VERSION ""

NS_ :

BS_:

BU_: XXX

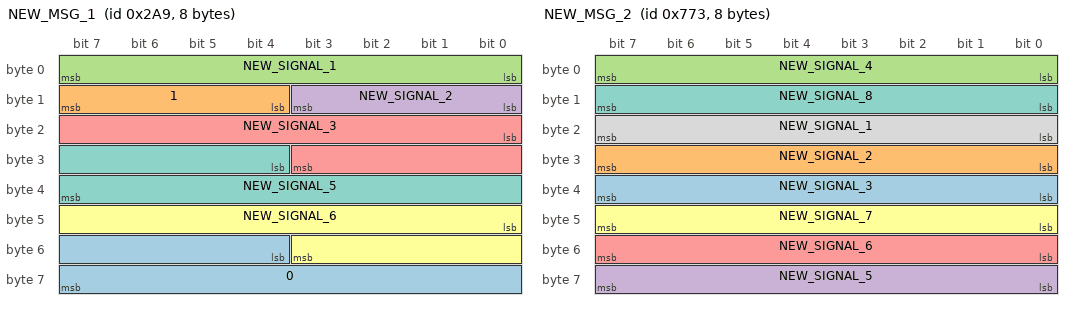
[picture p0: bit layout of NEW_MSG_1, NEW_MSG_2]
BO_ 681 NEW_MSG_1: 8 XXX
 SG_ 0 : 52|12@1+ (1,0) [0|4095] "" XXX
 SG_ 1 : 15|4@0+ (1,0) [0|15] "" XXX
 SG_ NEW_SIGNAL_1 : 0|8@1+ (1,0) [0|255] "" XXX
 SG_ NEW_SIGNAL_2 : 8|4@1+ (1,0) [0|15] "" XXX
 SG_ NEW_SIGNAL_3 : 16|12@1+ (1,0) [0|255] "" XXX
 SG_ NEW_SIGNAL_6 : 40|12@1+ (1,0) [0|255] "" XXX
 SG_ NEW_SIGNAL_5 : 28|12@1+ (1,0) [0|255] "" XXX

BO_ 1907 NEW_MSG_2: 8 XXX
 SG_ NEW_SIGNAL_3 : 32|8@1+ (1,0) [0|255] "" XXX
 SG_ NEW_SIGNAL_2 : 24|8@1+ (1,0) [0|255] "" XXX
 SG_ NEW_SIGNAL_4 : 0|8@1+ (1,0) [0|15] "" XXX
 SG_ NEW_SIGNAL_5 : 63|8@0+ (1,0) [0|255] "" XXX
 SG_ NEW_SIGNAL_6 : 55|8@0+ (1,0) [0|31] "" XXX
 SG_ NEW_SIGNAL_7 : 47|8@0+ (1,0) [0|255] "" XXX
 SG_ NEW_SIGNAL_8 : 8|8@1+ (1,0) [0|255] "" XXX
 SG_ NEW_SIGNAL_1 : 23|8@0+ (1,0) [0|255] "" XXX

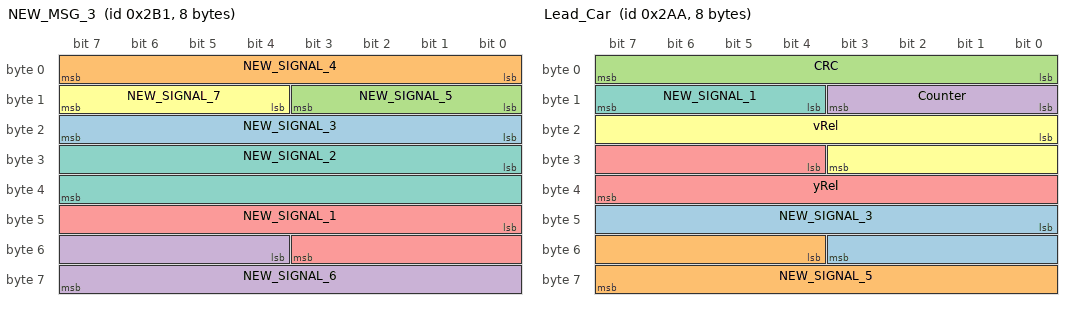
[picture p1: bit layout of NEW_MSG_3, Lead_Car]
BO_ 689 NEW_MSG_3: 8 XXX
 SG_ NEW_SIGNAL_3 : 16|8@1+ (1,0) [0|127] "" XXX
 SG_ NEW_SIGNAL_4 : 0|8@1+ (1,0) [0|63] "" XXX
 SG_ NEW_SIGNAL_5 : 8|4@1+ (1,0) [0|7] "" XXX
 SG_ NEW_SIGNAL_6 : 52|12@1+ (1,0) [0|4095] "" XXX
 SG_ NEW_SIGNAL_1 : 40|12@1+ (-1,2047) [0|255] "" XXX
 SG_ NEW_SIGNAL_7 : 15|4@0+ (1,0) [0|15] "" XXX
 SG_ NEW_SIGNAL_2 : 24|16@1+ (-1,32212) [0|255] "" XXX

BO_ 682 Lead_Car: 8 XXX
 SG_ NEW_SIGNAL_3 : 40|12@1+ (1,0) [0|255] "" XXX
 SG_ NEW_SIGNAL_5 : 52|12@1+ (1,0) [0|4095] "" XXX
 SG_ CRC : 0|8@1+ (1,0) [0|255] "" XXX
 SG_ Counter : 8|4@1+ (1,0) [0|15] "" XXX
 SG_ yRel : 28|12@1+ (1,-2047) [0|255] "" XXX
 SG_ vRel : 16|12@1+ (1,-2047) [0|255] "" XXX
 SG_ NEW_SIGNAL_1 : 15|4@0+ (1,0) [0|15] "" XXX

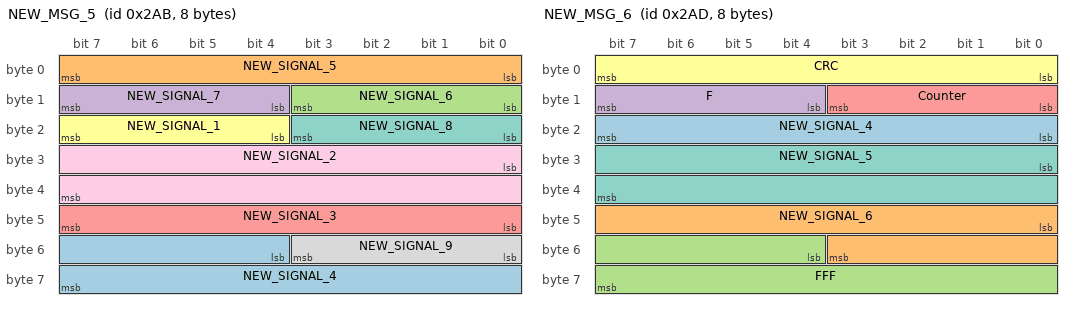
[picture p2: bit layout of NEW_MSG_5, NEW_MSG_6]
BO_ 683 NEW_MSG_5: 8 XXX
 SG_ NEW_SIGNAL_4 : 52|12@1+ (1,0) [0|63] "" XXX
 SG_ NEW_SIGNAL_5 : 0|8@1+ (1,0) [0|255] "" XXX
 SG_ NEW_SIGNAL_6 : 8|4@1+ (1,0) [0|15] "" XXX
 SG_ NEW_SIGNAL_7 : 15|4@0+ (1,0) [0|15] "" XXX
 SG_ NEW_SIGNAL_3 : 40|8@1+ (1,-368) [0|2047] "" XXX
 SG_ NEW_SIGNAL_1 : 20|4@1- (1,0) [0|4095] "" XXX
 SG_ NEW_SIGNAL_8 : 16|4@1+ (1,0) [0|15] "" XXX
 SG_ NEW_SIGNAL_9 : 48|4@1+ (1,0) [0|15] "" XXX
 SG_ NEW_SIGNAL_2 : 24|16@1+ (1,-28723) [0|63] "" XXX

BO_ 685 NEW_MSG_6: 8 XXX
 SG_ NEW_SIGNAL_4 : 16|8@1+ (1,0) [0|4095] "" XXX
 SG_ NEW_SIGNAL_6 : 40|12@1+ (-1,2047) [0|4095] "" XXX
 SG_ FFF : 52|12@1+ (1,0) [0|4095] "" XXX
 SG_ F : 15|4@0+ (1,0) [0|15] "" XXX
 SG_ Counter : 8|4@1+ (1,0) [0|15] "" XXX
 SG_ CRC : 0|8@1+ (1,0) [0|255] "" XXX
 SG_ NEW_SIGNAL_5 : 24|16@1+ (-1,32212) [0|4095] "" XXX

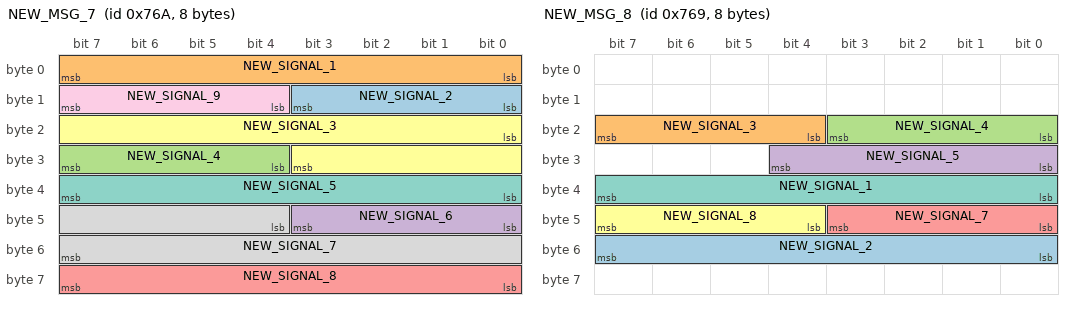
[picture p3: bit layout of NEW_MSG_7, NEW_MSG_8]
BO_ 1898 NEW_MSG_7: 8 XXX
 SG_ NEW_SIGNAL_2 : 11|4@0+ (1,0) [0|255] "" XXX
 SG_ NEW_SIGNAL_1 : 0|8@1+ (1,0) [0|255] "" XXX
 SG_ NEW_SIGNAL_4 : 31|4@0+ (1,0) [0|255] "" XXX
 SG_ NEW_SIGNAL_6 : 43|4@0+ (1,0) [0|255] "" XXX
 SG_ NEW_SIGNAL_8 : 63|8@0+ (1,0) [0|255] "" XXX
 SG_ NEW_SIGNAL_3 : 16|12@1+ (1,0) [0|255] "" XXX
 SG_ NEW_SIGNAL_5 : 32|8@1+ (1,0) [0|255] "" XXX
 SG_ NEW_SIGNAL_7 : 44|12@1+ (1,0) [0|255] "" XXX
 SG_ NEW_SIGNAL_9 : 15|4@0+ (1,0) [0|15] "" XXX

BO_ 1897 NEW_MSG_8: 8 XXX
 SG_ NEW_SIGNAL_2 : 55|8@0+ (1,0) [0|4095] "" XXX
 SG_ NEW_SIGNAL_3 : 20|4@1+ (1,0) [0|255] "" XXX
 SG_ NEW_SIGNAL_4 : 16|4@1+ (1,0) [0|15] "" XXX
 SG_ NEW_SIGNAL_5 : 24|5@1+ (1,0) [0|15] "" XXX
 SG_ NEW_SIGNAL_7 : 40|4@1+ (1,0) [0|31] "" XXX
 SG_ NEW_SIGNAL_8 : 47|4@0+ (1,0) [0|15] "" XXX
 SG_ NEW_SIGNAL_1 : 39|8@0+ (1,0) [0|4095] "" XXX

BO_ 1910 NEW_MSG_4: 8 XXX
 SG_ NEW_SIGNAL_1 : 16|12@1+ (1,0) [0|255] "" XXX
 SG_ NEW_SIGNAL_2 : 28|12@1+ (1,0) [0|4095] "" XXX
